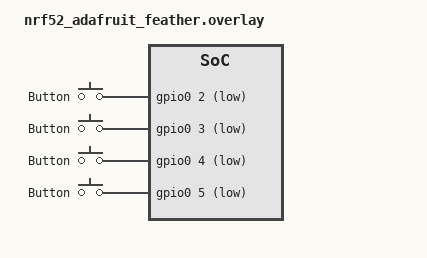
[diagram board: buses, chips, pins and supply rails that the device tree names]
/ {
	aliases {
			sw0 = &button0;
			sw1 = &button1;
			sw2 = &button2;
			sw3 = &button3;
	};
	buttons {
		compatible = "gpio-keys";
		button0: button_0 {
			gpios = <&gpio0 2 (GPIO_PULL_UP | GPIO_ACTIVE_LOW)>;
			label = "Button";
		};
		button1: button_1 {
			gpios = <&gpio0 3 (GPIO_PULL_UP | GPIO_ACTIVE_LOW)>;
			label = "Button";
		};
		button2: button_2 {
			gpios = <&gpio0 4 (GPIO_PULL_UP | GPIO_ACTIVE_LOW)>;
			label = "Button";
		};
		button3: button_3 {
			gpios = <&gpio0 5 (GPIO_PULL_UP | GPIO_ACTIVE_LOW)>;
			label = "Button";
		};
	};
};
